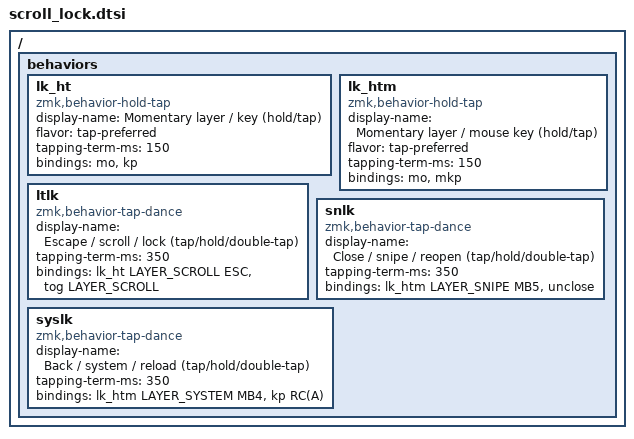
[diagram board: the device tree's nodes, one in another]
/*
 * Custom lock / multi-tap behaviors for sticky trackball layers.
 *
 * Scroll (pos1 / &ltlk):
 *   tap         -> Escape
 *   hold        -> momentary LAYER_SCROLL
 *   double-tap  -> lock/unlock LAYER_SCROLL
 *
 * Snipe (pos6 / &snlk):
 *   tap         -> Close (MB5)
 *   hold        -> momentary LAYER_SNIPE
 *   double-tap  -> reopen closed tab (&unclose)
 * Sticky snipe lock/unlock is a combo of the lower two buttons (see combos.dtsi).
 *
 * Media is momentary on pos0 (Enter tap / Media hold / 2× Undo via &entlk)
 * and sits above Snipe in the layer stack so its encoders win while held.
 * Tap keys on pos6/pos7 are Close (MB5) on the snipe button and Back (MB4)
 * on the system button (kp-only swap vs the hold layers).
 *
 * IMPORTANT ordering: each is a tap-dance (outer) wrapping a hold-tap (inner).
 * The reverse -- a hold-tap wrapping a tap-dance -- does NOT work: each tap
 * resolves through the hold-tap separately, so the inner tap-dance never counts
 * to two and the double-tap never fires. With the tap-dance on the outside
 * it owns the tap counting, and its timer passes a held press straight through
 * to the inner hold-tap (so hold still reaches the layer).
 *
 * Trade-off: because the same key must wait to see whether a second tap is
 * coming, the momentary-layer hold has some added latency.
 *
 * Bound in the keymap as `&ltlk` (scroll), `&snlk` (snipe), and `&syslk`
 * (back / system / reload). All are 0-cell (the layer + tap key are baked in
 * below). LAYER_SCROLL / LAYER_SNIPE / LAYER_SYSTEM must be defined (in the
 * keymap) before this file is included. `&unclose` is defined in
 * edit_extras.dtsi (phandle resolves after the full tree is built).
 */

/ {
	behaviors {
		// Shared inner hold-tap: hold -> &mo <layer>, tap -> &kp <key>.
		lk_ht: lk_ht {
			compatible = "zmk,behavior-hold-tap";
			display-name = "Momentary layer / key (hold/tap)";
			#binding-cells = <2>;
			flavor = "tap-preferred";
			tapping-term-ms = <150>;
			bindings = <&mo>, <&kp>;
		};

		// Same as lk_ht but tap is a mouse button (&mkp).
		lk_htm: lk_htm {
			compatible = "zmk,behavior-hold-tap";
			display-name = "Momentary layer / mouse key (hold/tap)";
			#binding-cells = <2>;
			flavor = "tap-preferred";
			tapping-term-ms = <150>;
			bindings = <&mo>, <&mkp>;
		};

		ltlk: ltlk {
			compatible = "zmk,behavior-tap-dance";
			display-name = "Escape / scroll / lock (tap/hold/double-tap)";
			#binding-cells = <0>;
			// Was 200 ms — too short to reliably double-tap lock.
			tapping-term-ms = <350>;
			bindings = <&lk_ht LAYER_SCROLL ESC>, <&tog LAYER_SCROLL>;
		};

		/* pos6: hold = snipe; tap = Close (MB5); 2× = reopen tab.
		 * Sticky snipe lock is combo pos6+7. Back lives on syslk. */
		snlk: snlk {
			compatible = "zmk,behavior-tap-dance";
			display-name = "Close / snipe / reopen (tap/hold/double-tap)";
			#binding-cells = <0>;
			tapping-term-ms = <350>;
			bindings = <&lk_htm LAYER_SNIPE MB5>, <&unclose>;
		};

		/* pos7: hold = System; tap = Back (MB4); double-tap = reload.
		 * Tap-dance stays outside the hold-tap, same reason as ltlk/snlk.
		 */
		syslk: syslk {
			compatible = "zmk,behavior-tap-dance";
			display-name = "Back / system / reload (tap/hold/double-tap)";
			#binding-cells = <0>;
			tapping-term-ms = <350>;
			bindings = <&lk_htm LAYER_SYSTEM MB4>, <&kp RC(A)>;
		};
	};
};
